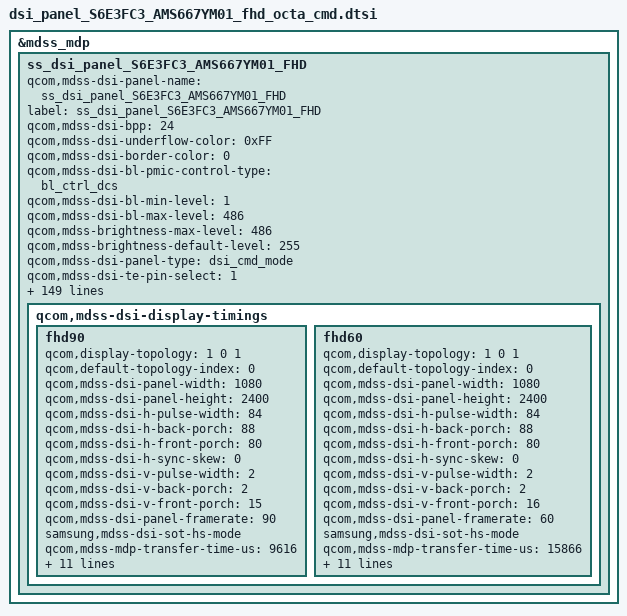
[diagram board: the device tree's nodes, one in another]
/* Copyright (c) 2020, Samsung Electronics Corporation. All rights reserved.
 *
 * This program is free software; you can redistribute it and/or modify
 * it under the terms of the GNU General Public License version 2 and
 * only version 2 as published by the Free Software Foundation.
 *
 * This program is distributed in the hope that it will be useful,
 * but WITHOUT ANY WARRANTY; without even the implied warranty of
 * MERCHANTABILITY or FITNESS FOR A PARTICULAR PURPOSE.  See the
 * GNU General Public License for more details.
 */

&mdss_mdp {
	ss_dsi_panel_S6E3FC3_AMS667YM01_FHD: ss_dsi_panel_S6E3FC3_AMS667YM01_FHD {
		qcom,mdss-dsi-panel-name = "ss_dsi_panel_S6E3FC3_AMS667YM01_FHD";
		label = "ss_dsi_panel_S6E3FC3_AMS667YM01_FHD";

		qcom,mdss-dsi-bpp = <24>;

		qcom,mdss-dsi-underflow-color = <0xFF>;
		qcom,mdss-dsi-border-color = <0>;

		qcom,mdss-dsi-bl-pmic-control-type = "bl_ctrl_dcs";

		qcom,mdss-dsi-bl-min-level = <1>;
		qcom,mdss-dsi-bl-max-level = <486>;
		qcom,mdss-brightness-max-level = <486>;
		qcom,mdss-brightness-default-level = <255>;

		qcom,mdss-dsi-panel-type = "dsi_cmd_mode";

		qcom,mdss-dsi-te-pin-select = <1>;

		qcom,mdss-dsi-te-dcs-command = <1>;
		qcom,mdss-dsi-wr-mem-start = <0x2C>;
		qcom,mdss-dsi-wr-mem-continue = <0x3C>;

		qcom,mdss-dsi-pixel-packing = "loose";

		qcom,mdss-dsi-virtual-channel-id = <0>;
		qcom,mdss-dsi-color-order = "rgb_swap_rgb";
		qcom,mdss-dsi-lane-0-state;
		qcom,mdss-dsi-lane-1-state;
		qcom,mdss-dsi-lane-2-state;
		qcom,mdss-dsi-lane-3-state;
		qcom,mdss-dsi-lane-map = "lane_map_0123";

		qcom,mdss-dsi-t-clk-pre = <0x3E>;
		qcom,mdss-dsi-t-clk-post = <0x10>;

		qcom,mdss-dsi-stream = <0>;
		qcom,mdss-dsi-mdp-trigger = "none";
		qcom,mdss-dsi-dma-trigger = "trigger_sw";

		qcom,mdss-pan-physical-width-dimension = <70>; /* 69.87 */
		qcom,mdss-pan-physical-height-dimension = <155>; /* 155.28 */

		qcom,mdss-dsi-reset-sequence = <0 10>, <1 10>;

		qcom,mdss-dsi-lp11-init;
		/*qcom,mdss-dsi-init-delay-us = <1000>;*/

		qcom,mdss-dsi-t-clk-pre-extend; /* Increment t_clk_pre counter by 2 byteclk */
		qcom,mdss-dsi-rx-eot-ignore;
		qcom,mdss-dsi-tx-eot-append;

		/* HDR Setting */
		/*qcom,mdss-dsi-panel-hdr-enabled;*/
		/*qcom,mdss-dsi-panel-hdr-color-primaries = <15635 16450 34000 16000 13250 34500 7500 3000>;*/
		/*qcom,mdss-dsi-panel-peak-brightness = <5400000>;*/
		/*qcom,mdss-dsi-panel-average-brightness = <2000000>;*/
		/*qcom,mdss-dsi-panel-blackness-level = <2000>;*/

		qcom,ulps-enabled;

		/* qcom,suspend-ulps-enabled; */
		//qcom,esd-check-enabled;
		//qcom,mdss-dsi-panel-status-check-mode ="irq_check";
		/*qcom,mdss-dsi-panel-status-read-length;*/
		/*qcom,mdss-dsi-panel-status-value;*/
		/*qcom,mdss-dsi-panel-status-irq-trigger1 = "rising";*/

		/* *************************************************************
		 * Below  parameters are samsung dependent thigs
		 * *************************************************************
		 */
		samsung,panel-vendor = "SDC";
		samsung,disp-model = "AMS667YM01";
		samsung,support_gamma_mode2;
		samsung,skip_read_on_pre;
		samsung,elvss_interpolation_temperature = <(-16)>;
		samsung,support_lpm;
		samsung,support_gpara;
		samsung,pointing_gpara;
		samsung,two_byte_gpara;
		samsung,rsc_4_frame_idle;
		samsung,support_factory_panel_swap;

		samsung,support-optical-fingerprint;

		samsung,support_vrr_based_bl; /* VRR Variable Refresh Rate */

		//samsung,esd-irq-trigger1 = "falling"; /* DISP_DET */
		//samsung,esd-irq-trigger2 = "falling"; /* FG_ERR */

		/* *************************************************************
		 *  SELF DISPLAY
		 * *************************************************************
		 */

		ss,self_display = <&self_display_FC3_dtsi>;

		/* *************************************************************
		 *  Tx
		 * *************************************************************
		 */

		samsung,level0_key_enable_tx_cmds_revA	= [29 01 00 00 00 00 03 9F A5 A5]; /* PASSWD0 */
		samsung,level0_key_disable_tx_cmds_revA	= [29 01 00 00 00 00 03 9F 5A 5A]; /* PASSWD0 */
		samsung,level1_key_enable_tx_cmds_revA	= [29 01 00 00 00 00 03 F0 5A 5A]; /* PASSWD1 */
		samsung,level1_key_disable_tx_cmds_revA	= [29 01 00 00 00 00 03 F0 A5 A5]; /* PASSWD1 */
		samsung,level2_key_enable_tx_cmds_revA	= [29 01 00 00 00 00 03 FC 5A 5A];
		samsung,level2_key_disable_tx_cmds_revA	= [29 01 00 00 00 00 03 FC A5 A5];

		/* BRIGHTNESS_MAX_PACKET = 50 */
		samsung,brightness_tx_cmds_revA = [
			39 01 00 00 00 00 01 00
			39 01 00 00 00 00 01 00
			39 01 00 00 00 00 01 00
			39 01 00 00 00 00 01 00
			39 01 00 00 00 00 01 00
			39 01 00 00 00 00 01 00
			39 01 00 00 00 00 01 00
			39 01 00 00 00 00 01 00
			39 01 00 00 00 00 01 00
			39 01 00 00 00 00 01 00
			39 01 00 00 00 00 01 00
			39 01 00 00 00 00 01 00
			39 01 00 00 00 00 01 00
			39 01 00 00 00 00 01 00
			39 01 00 00 00 00 01 00
			39 01 00 00 00 00 01 00
			39 01 00 00 00 00 01 00
			39 01 00 00 00 00 01 00
			39 01 00 00 00 00 01 00
			39 01 00 00 00 00 01 00
			39 01 00 00 00 00 01 00
			39 01 00 00 00 00 01 00
			39 01 00 00 00 00 01 00
			39 01 00 00 00 00 01 00
			39 01 00 00 00 00 01 00
			39 01 00 00 00 00 01 00
			39 01 00 00 00 00 01 00
			39 01 00 00 00 00 01 00
			39 01 00 00 00 00 01 00
			39 01 00 00 00 00 01 00
			39 01 00 00 00 00 01 00
			39 01 00 00 00 00 01 00
			39 01 00 00 00 00 01 00
			39 01 00 00 00 00 01 00
			39 01 00 00 00 00 01 00
			39 01 00 00 00 00 01 00
			39 01 00 00 00 00 01 00
			39 01 00 00 00 00 01 00
			39 01 00 00 00 00 01 00
			39 01 00 00 00 00 01 00
			39 01 00 00 00 00 01 00
			39 01 00 00 00 00 01 00
			39 01 00 00 00 00 01 00
			39 01 00 00 00 00 01 00
			39 01 00 00 00 00 01 00
			39 01 00 00 00 00 01 00
			39 01 00 00 00 00 01 00
			39 01 00 00 00 00 01 00
			39 01 00 00 00 00 01 00
			39 01 00 00 00 00 01 00
		];

		samsung,display_on_tx_cmds_revA = [
			/* DSC PPS cmd unlock & lock LEVEL0 KEY */
			29 00 00 00 00 00 03 9F A5 A5
			05 00 00 00 00 00 02 29 00
			29 01 00 00 00 00 03 9F 5A 5A
		];

		samsung,display_off_tx_cmds_revA = [05 01 00 00 00 00 02 28 00];

		samsung,reg_read_pos_tx_cmds_revA = [29 00 00 00 00 00 04 B0 00 00 00];

		samsung,mtp_write_sysfs_tx_cmds_revA = [
			29 00 00 00 00 00 3D 00
			00 00 00 00 00 00 00 00 00 00
			00 00 00 00 00 00 00 00 00 00
			00 00 00 00 00 00 00 00 00 00
			00 00 00 00 00 00 00 00 00 00
			00 00 00 00 00 00 00 00 00 00
			00 00 00 00 00 00 00 00 00 00
		];

		samsung,panel_ltps_tx_cmds_revA = [
			29 00 00 00 00 00 03 F0 5A 5A
			29 00 00 00 00 00 03 9F A5 A5

			/* Global Para Setting */
			29 00 00 00 00 00 2A F2
				00 05 0E 58 50 01 0C 00
				04 26 E4 2F B0 0C 09 74
				26 E4 0C 00 04 10 00 10
				26 A8 10 00 10 10 3C 10
				00 40 30 C8 00 C8 00 00
				CE

			/* Freq setting */
			29 00 00 00 00 00 04 B0 00 27 F2
			29 00 00 00 00 00 02 F2 00

			/* Panel Update */
			29 00 00 00 00 00 02 F7 0F

			29 00 00 00 00 00 03 9F 5A 5A
			29 01 00 00 00 00 03 F0 A5 A5
		];

		samsung,panel_ltps_tx_cmds_revC = [
			29 00 00 00 00 00 03 F0 5A 5A
			29 00 00 00 00 00 03 9F A5 A5

			/* Global Para Setting */
			29 00 00 00 00 00 2A F2
				00 05 0E 58 50 00 0C 00
				04 31 48 31 48 0C 04 BC
				26 E8 0C 00 04 10 00 10
				26 A8 10 00 10 10 3C 10
				00 40 30 C8 00 C8 00 00
				CE
			/* Freq setting */
			29 00 00 00 00 00 04 B0 00 27 F2
			29 00 00 00 00 00 02 F2 00

			/* Panel Update */
			29 00 00 00 00 00 02 F7 0F

			29 00 00 00 00 00 03 9F 5A 5A
			29 01 00 00 00 00 03 F0 A5 A5
		];

		samsung,smooth_dimming_off_tx_cmds_revA = [
			29 00 00 00 00 00 03 F0 5A 5A
			29 00 00 00 00 00 04 B0 00 91 63
			29 00 00 00 00 00 02 63 20
			29 01 00 00 11 00 02 53 20
			29 00 00 00 00 00 02 F7 0F
			29 01 00 00 00 00 03 F0 A5 A5
		];

		samsung,gamma_mode2_normal_tx_cmds_revG=[
			29 00 00 00 00 00 04 B0 00 91 63
			29 00 00 00 00 00 02 63 60	/* Dimming Speed Sync Control */
			29 00 00 00 00 00 04 B0 02 03 63
			29 00 00 00 00 00 03 63 f1 07	/* For Finger Print */
			29 00 00 00 00 00 02 53 20	/* Dimming Speed setting */
			29 00 00 00 00 00 03 51 03 FF	/* WRDISBV */
			29 00 00 00 00 00 02 B5 14	/* temperature */
			29 00 00 00 00 00 04 B0 02 03 63
			29 00 00 00 00 00 03 63 f0 00	/* For Finger Print */
			29 00 00 00 00 00 04 B0 00 76 63
			29 00 00 00 00 00 04 63 00 00 00 /* AOR */
		];

		samsung,gamma_mode2_normal_tx_cmds_revF=[
			29 00 00 00 00 00 03 91 02 01	 /* normal brightness */
			29 00 00 00 00 00 02 53 20	/* dimming speed setting */
			29 00 00 00 00 00 03 51 03 FF	/* WRDISBV */
			29 00 00 00 00 00 02 B5 14	/* temperature */
			29 00 00 00 00 00 04 B0 00 76 63
			29 00 00 00 00 00 04 63 00 00 00 /* AOR */
		];

		samsung,gamma_mode2_normal_tx_cmds_revA=[
			29 00 00 00 00 00 04 B0 00 02 90
			29 00 00 00 00 00 02 90 1C	 /* normal brightness */
			29 00 00 00 00 00 02 53 20	/* dimming speed setting */
			29 00 00 00 00 00 03 51 03 FF	/* WRDISBV */
			29 00 00 00 00 00 02 B5 14	/* temperature */
			29 00 00 00 00 00 04 B0 00 76 63
			29 00 00 00 00 00 04 63 00 00 00 /* AOR */
		];

		samsung,gamma_mode2_hbm_tx_cmds_revG=[
			29 00 00 00 00 00 04 B0 00 91 63
			29 00 00 00 00 00 02 63 20	/* Dimming Speed Sync Control */
			29 00 00 00 00 00 04 B0 02 03 63
			29 00 00 00 00 00 03 63 f1 00	/* For Finger Print */
			29 00 00 00 00 00 02 53 E0	/* Dimming Speed setting */
			29 00 00 00 00 00 03 51 03 FF	/* WRDISBV */
			29 00 00 00 00 00 02 B5 14	/* temperature */
			29 00 00 00 00 00 04 B0 02 03 63
			29 00 00 00 00 00 03 63 f0 07	/* For Finger Print */
			29 00 00 00 00 00 04 B0 00 76 63
			29 00 00 00 00 00 04 63 00 00 00 /* AOR */
		];

		samsung,gamma_mode2_hbm_tx_cmds_revF=[
			29 00 00 00 00 00 03 91 02 00	 /* hbm brightness */
			29 00 00 00 00 00 02 53 E0	/* dimming speed setting */
			29 00 00 00 00 00 03 51 03 FF	/* WRDISBV */
			29 00 00 00 00 00 02 B5 14	/* temperature */
			29 00 00 00 00 00 04 B0 00 76 63
			29 00 00 00 00 00 04 63 00 00 00 /* AOR */
		];

		samsung,gamma_mode2_hbm_tx_cmds_revA=[
			29 00 00 00 00 00 04 B0 00 02 90
			29 00 00 00 00 00 02 90 14	 /* hbm brightness */
			29 00 00 00 00 00 02 53 E0	/* dimming speed setting */
			29 00 00 00 00 00 03 51 03 FF	/* WRDISBV */
			29 00 00 00 00 00 02 B5 14	/* temperature */
			29 00 00 00 00 00 04 B0 00 76 63
			29 00 00 00 00 00 04 63 00 00 00 /* AOR */
		];

		samsung,vrr_tx_cmds_revA = [
			29 00 00 00 00 00 03 60 00 00
			29 00 00 00 00 00 02 F7 0F
		];

		samsung,acl_on_tx_cmds_revA = [
			29 00 00 00 00 00 04 B0 03 B3 65
			29 00 00 00 00 00 14 65
				55 00 B0 51 66 98 15 55 55 55	/* 32 Frame Avg & ACL start step 50% */
				08 F1 C6 48 40 00 20 10 09	/* ACL Dimming : 32 frame */
			29 00 00 00 00 00 02 55 03		/* normal ACL 15% & HBM ACL 8% */
		];

		samsung,acl_off_tx_cmds_revA = [
			29 01 00 00 00 00 02 55 00	/* ACL OFF */
		];

		/* *************************************************************
		 *  Rx (Module Information READ)
		 * *************************************************************
		 */
		samsung,manufacture_id0_rx_cmds_revA	= [06 01 00 00 00 00 01 da 01 00 00];
		samsung,manufacture_id1_rx_cmds_revA	= [06 01 00 00 00 00 01 db 01 00 00];
		samsung,manufacture_id2_rx_cmds_revA	= [06 01 00 00 00 00 01 dc 01 00 00];

		samsung,module_info_rx_cmds_revA = [06 01 00 00 00 00 01 A1 0B 00 00];
		samsung,octa_id_rx_cmds_revA	= [06 01 00 00 00 00 01 A1 04 00 0B]; /* OCTA ID : read A1 12th ~ 15th + Cell ID */
		samsung,cell_id_rx_cmds_revA	= [06 01 00 00 00 00 01 A1 10 00 0F]; /* CELL ID : read A1 16th ~ 31th bytes*/
		samsung,cell_id_rx_cmds_revG	= [06 01 00 00 00 00 01 92 10 00 02]; /* CELL ID : read 92 3rd ~ 18th bytes*/
		samsung,ddi_id_rx_cmds_revA		= [06 01 00 00 00 00 01 D6 05 00 00];

		samsung,mtp_read_sysfs_rx_cmds_revA = [06 01 00 00 00 00 01 00 00 00 00];


		/* *************************************************************
		 * candela to index mappings
		 * **************************************************************
		 */
		samsung,candela_map_table_revA = < /* THIS TABLE USED FOR DIMMING */
		/* <idx> <from> <till> <gm2_wrdisbv> <cd> */
			0	0	0	2	2
			1	1	1	3	2
			2	2	2	4	3
			3	3	3	5	3
			4	4	4	7	4
			5	5	5	8	5
			6	6	6	10	5
			7	7	7	12	6
			8	8	8	13	7
			9	9	9	15	7
			10	10	10	17	8
			11	11	11	19	9
			12	12	12	21	10
			13	13	13	24	11
			14	14	14	26	12
			15	15	15	28	13
			16	16	16	30	13
			17	17	17	32	14
			18	18	18	35	15
			19	19	19	37	16
			20	20	20	40	17
			21	21	21	42	18
			22	22	22	45	19
			23	23	23	47	20
			24	24	24	50	21
			25	25	25	52	22
			26	26	26	55	23
			27	27	27	58	25
			28	28	28	60	26
			29	29	29	63	27
			30	30	30	66	28
			31	31	31	69	29
			32	32	32	71	30
			33	33	33	74	31
			34	34	34	77	32
			35	35	35	80	34
			36	36	36	83	35
			37	37	37	86	36
			38	38	38	89	37
			39	39	39	92	38
			40	40	40	95	40
			41	41	41	98	41
			42	42	42	101	42
			43	43	43	104	43
			44	44	44	107	45
			45	45	45	110	46
			46	46	46	113	47
			47	47	47	116	48
			48	48	48	119	50
			49	49	49	123	51
			50	50	50	126	52
			51	51	51	129	54
			52	52	52	132	55
			53	53	53	136	56
			54	54	54	139	58
			55	55	55	142	59
			56	56	56	146	60
			57	57	57	149	62
			58	58	58	152	63
			59	59	59	156	64
			60	60	60	159	66
			61	61	61	162	67
			62	62	62	166	68
			63	63	63	169	70
			64	64	64	173	71
			65	65	65	176	73
			66	66	66	180	74
			67	67	67	183	76
			68	68	68	187	77
			69	69	69	190	78
			70	70	70	194	80
			71	71	71	197	81
			72	72	72	201	83
			73	73	73	205	84
			74	74	74	208	86
			75	75	75	212	87
			76	76	76	215	89
			77	77	77	219	90
			78	78	78	223	92
			79	79	79	227	93
			80	80	80	230	95
			81	81	81	234	96
			82	82	82	238	98
			83	83	83	241	99
			84	84	84	245	101
			85	85	85	249	102
			86	86	86	253	104
			87	87	87	257	105
			88	88	88	260	107
			89	89	89	264	108
			90	90	90	268	110
			91	91	91	272	112
			92	92	92	276	113
			93	93	93	280	115
			94	94	94	283	116
			95	95	95	287	118
			96	96	96	291	119
			97	97	97	295	121
			98	98	98	299	123
			99	99	99	303	124
			100	100	100	307	126
			101	101	101	311	127
			102	102	102	315	129
			103	103	103	319	131
			104	104	104	323	132
			105	105	105	327	134
			106	106	106	331	136
			107	107	107	335	137
			108	108	108	339	139
			109	109	109	343	140
			110	110	110	347	142
			111	111	111	351	144
			112	112	112	355	145
			113	113	113	360	147
			114	114	114	364	149
			115	115	115	368	150
			116	116	116	372	152
			117	117	117	376	154
			118	118	118	380	156
			119	119	119	384	157
			120	120	120	389	159
			121	121	121	393	161
			122	122	122	397	162
			123	123	123	401	164
			124	124	124	405	166
			125	125	125	410	167
			126	126	126	414	169
			127	127	127	418	171
			128	128	128	422	173
			129	129	129	427	174
			130	130	130	431	176
			131	131	131	435	178
			132	132	132	440	180
			133	133	133	444	181
			134	134	134	448	183
			135	135	135	453	185
			136	136	136	457	187
			137	137	137	461	188
			138	138	138	465	190
			139	139	139	470	192
			140	140	140	474	194
			141	141	141	478	195
			142	142	142	483	197
			143	143	143	487	199
			144	144	144	491	201
			145	145	145	496	203
			146	146	146	500	204
			147	147	147	504	206
			148	148	148	509	208
			149	149	149	513	210
			150	150	150	518	212
			151	151	151	522	214
			152	152	152	526	215
			153	153	153	531	217
			154	154	154	535	219
			155	155	155	540	221
			156	156	156	544	223
			157	157	157	549	225
			158	158	158	553	226
			159	159	159	558	228
			160	160	160	562	230
			161	161	161	567	232
			162	162	162	571	234
			163	163	163	576	236
			164	164	164	580	237
			165	165	165	585	239
			166	166	166	589	241
			167	167	167	594	243
			168	168	168	598	245
			169	169	169	603	247
			170	170	170	608	249
			171	171	171	612	251
			172	172	172	617	253
			173	173	173	621	254
			174	174	174	626	256
			175	175	175	631	258
			176	176	176	635	260
			177	177	177	640	262
			178	178	178	644	264
			179	179	179	649	266
			180	180	180	654	268
			181	181	181	658	270
			182	182	182	663	272
			183	183	183	668	274
			184	184	184	672	275
			185	185	185	677	277
			186	186	186	682	279
			187	187	187	686	281
			188	188	188	691	283
			189	189	189	696	285
			190	190	190	701	287
			191	191	191	705	289
			192	192	192	710	291
			193	193	193	715	293
			194	194	194	720	295
			195	195	195	724	297
			196	196	196	729	299
			197	197	197	734	301
			198	198	198	739	303
			199	199	199	744	305
			200	200	200	748	307
			201	201	201	753	309
			202	202	202	758	311
			203	203	203	763	313
			204	204	204	768	315
			205	205	205	772	317
			206	206	206	777	319
			207	207	207	782	321
			208	208	208	787	323
			209	209	209	792	325
			210	210	210	797	327
			211	211	211	802	329
			212	212	212	807	331
			213	213	213	811	333
			214	214	214	816	335
			215	215	215	821	337
			216	216	216	826	339
			217	217	217	831	341
			218	218	218	836	343
			219	219	219	841	345
			220	220	220	846	347
			221	221	221	851	349
			222	222	222	856	351
			223	223	223	861	353
			224	224	224	866	355
			225	225	225	871	357
			226	226	226	876	359
			227	227	227	881	361
			228	228	228	886	363
			229	229	229	891	365
			230	230	230	896	368
			231	231	231	901	370
			232	232	232	906	372
			233	233	233	911	374
			234	234	234	916	376
			235	235	235	921	378
			236	236	236	926	380
			237	237	237	931	382
			238	238	238	936	384
			239	239	239	941	386
			240	240	240	946	388
			241	241	241	951	390
			242	242	242	956	393
			243	243	243	961	395
			244	244	244	967	397
			245	245	245	972	399
			246	246	246	977	401
			247	247	247	982	403
			248	248	248	987	405
			249	249	249	992	407
			250	250	250	997	409
			251	251	251	1002	411
			252	252	252	1008	414
			253	253	253	1013	416
			254	254	254	1018	418
			255	255	255	1023	420
		>;

		samsung,hbm_candela_map_table_revG = <
		/* <idx> <from> <till> <gm2_wrdisbv> <cd>*/
			0	256	256	0	425
			1	257	257	2	426
			2	258	258	4	428
			3	259	259	6	430
			4	260	260	8	432
			5	261	261	10	433
			6	262	262	12	435
			7	263	263	14	436
			8	264	264	16	438
			9	265	265	18	440
			10	266	266	20	441
			11	267	267	22	443
			12	268	268	24	444
			13	269	269	26	446
			14	270	270	28	448
			15	271	271	30	450
			16	272	272	32	451
			17	273	273	34	453
			18	274	274	36	454
			19	275	275	37	456
			20	276	276	38	458
			21	277	277	39	459
			22	278	278	40	461
			23	279	279	41	462
			24	280	280	42	464
			25	281	281	43	466
			26	282	282	44	468
			27	283	283	45	469
			28	284	284	46	471
			29	285	285	47	472
			30	286	286	48	474
			31	287	287	49	476
			32	288	288	50	477
			33	289	289	51	479
			34	290	290	52	480
			35	291	291	53	482
			36	292	292	54	484
			37	293	293	55	485
			38	294	294	56	487
			39	295	295	57	488
			40	296	296	58	490
			41	297	297	59	492
			42	298	298	60	494
			43	299	299	61	495
			44	300	300	62	497
			45	301	301	63	498
			46	302	302	64	500
			47	303	303	65	502
			48	304	304	66	503
			49	305	305	67	505
			50	306	306	68	506
			51	307	307	69	508
			52	308	308	70	510
			53	309	309	71	512
			54	310	310	72	513
			55	311	311	73	515
			56	312	312	74	516
			57	313	313	75	518
			58	314	314	76	520
			59	315	315	77	521
			60	316	316	78	523
			61	317	317	79	524
			62	318	318	80	526
			63	319	319	81	528
			64	320	320	82	529
			65	321	321	83	531
			66	322	322	84	533
			67	323	323	85	534
			68	324	324	86	536
			69	325	325	87	538
			70	326	326	88	539
			71	327	327	89	541
			72	328	328	90	542
			73	329	329	91	544
			74	330	330	92	546
			75	331	331	93	547
			76	332	332	95	549
			77	333	333	97	550
			78	334	334	99	552
			79	335	335	101	554
			80	336	336	103	555
			81	337	337	105	557
			82	338	338	107	559
			83	339	339	109	560
			84	340	340	111	562
			85	341	341	113	564
			86	342	342	115	565
			87	343	343	117	567
			88	344	344	119	568
			89	345	345	121	570
			90	346	346	123	572
			91	347	347	125	573
			92	348	348	127	575
			93	349	349	129	577
			94	350	350	131	578
			95	351	351	133	580
			96	352	352	135	582
			97	353	353	137	583
			98	354	354	139	585
			99	355	355	141	586
			100	356	356	143	588
			101	357	357	145	590
			102	358	358	147	591
			103	359	359	149	593
			104	360	360	151	595
			105	361	361	154	596
			106	362	362	157	598
			107	363	363	160	599
			108	364	364	163	601
			109	365	365	166	603
			110	366	366	168	604
			111	367	367	171	606
			112	368	368	174	608
			113	369	369	177	609
			114	370	370	180	611
			115	371	371	183	612
			116	372	372	186	614
			117	373	373	189	616
			118	374	374	192	617
			119	375	375	195	619
			120	376	376	198	621
			121	377	377	201	622
			122	378	378	204	624
			123	379	379	207	626
			124	380	380	210	627
			125	381	381	213	629
			126	382	382	216	630
			127	383	383	219	632
			128	384	384	222	634
			129	385	385	225	635
			130	386	386	228	637
			131	387	387	231	639
			132	388	388	234	640
			133	389	389	237	642
			134	390	390	240	643
			135	391	391	243	645
			136	392	392	246	647
			137	393	393	249	648
			138	394	394	252	650
			139	395	395	255	652
			140	396	396	258	653
			141	397	397	261	655
			142	398	398	264	657
			143	399	399	267	658
			144	400	400	270	660
			145	401	401	273	661
			146	402	402	276	663
			147	403	403	279	665
			148	404	404	282	666
			149	405	405	285	668
			150	406	406	288	670
			151	407	407	291	671
			152	408	408	294	673
			153	409	409	297	675
			154	410	410	300	676
			155	411	411	303	678
			156	412	412	306	679
			157	413	413	309	681
			158	414	414	312	683
			159	415	415	315	684
			160	416	416	318	686
			161	417	417	321	687
			162	418	418	324	689
			163	419	419	327	691
			164	420	420	330	692
			165	421	421	333	694
			166	422	422	336	696
			167	423	423	339	697
			168	424	424	342	699
			169	425	425	345	701
			170	426	426	348	702
			171	427	427	351	704
			172	428	428	354	705
			173	429	429	357	707
			174	430	430	360	709
			175	431	431	363	710
			176	432	432	366	712
			177	433	433	369	713
			178	434	434	372	715
			179	435	435	375	717
			180	436	436	378	719
			181	437	437	381	720
			182	438	438	384	722
			183	439	439	387	723
			184	440	440	390	725
			185	441	441	393	727
			186	442	442	396	728
			187	443	443	399	730
			188	444	444	402	731
			189	445	445	405	733
			190	446	446	408	735
			191	447	447	411	737
			192	448	448	414	738
			193	449	449	417	740
			194	450	450	420	741
			195	451	451	423	743
			196	452	452	426	745
			197	453	453	429	746
			198	454	454	432	748
			199	455	455	435	749
			200	456	456	438	751
			201	457	457	441	753
			202	458	458	444	754
			203	459	459	447	756
			204	460	460	450	757
			205	461	461	453	759
			206	462	462	456	761
			207	463	463	459	763
			208	464	464	462	764
			209	465	465	465	766
			210	466	466	468	767
			211	467	467	471	769
			212	468	468	474	771
			213	469	469	477	772
			214	470	470	480	774
			215	471	471	483	775
			216	472	472	486	777
			217	473	473	489	779
			218	474	474	492	781
			219	475	475	495	782
			220	476	476	498	784
			221	477	477	501	785
			222	478	478	504	787
			223	479	479	507	789
			224	480	480	510	790
			225	481	481	513	792
			226	482	482	516	793
			227	483	483	519	795
			228	484	484	522	797
			229	485	485	525	799
			230	486	486	528	800
		>;

		samsung,hbm_candela_map_table_revA = <
		/* <idx> <from> <till> <gm2_wrdisbv> <cd>*/
			0	256	256	0	425
			1	257	257	3	426
			2	258	258	6	428
			3	259	259	9	430
			4	260	260	12	432
			5	261	261	15	433
			6	262	262	18	435
			7	263	263	21	436
			8	264	264	24	438
			9	265	265	27	440
			10	266	266	30	441
			11	267	267	33	443
			12	268	268	36	444
			13	269	269	39	446
			14	270	270	42	448
			15	271	271	45	450
			16	272	272	48	451
			17	273	273	51	453
			18	274	274	54	454
			19	275	275	57	456
			20	276	276	60	458
			21	277	277	63	459
			22	278	278	66	461
			23	279	279	69	462
			24	280	280	72	464
			25	281	281	75	466
			26	282	282	78	468
			27	283	283	81	469
			28	284	284	84	471
			29	285	285	86	472
			30	286	286	88	474
			31	287	287	90	476
			32	288	288	92	477
			33	289	289	94	479
			34	290	290	96	480
			35	291	291	98	482
			36	292	292	100	484
			37	293	293	102	485
			38	294	294	104	487
			39	295	295	106	488
			40	296	296	108	490
			41	297	297	110	492
			42	298	298	112	494
			43	299	299	114	495
			44	300	300	116	497
			45	301	301	118	498
			46	302	302	120	500
			47	303	303	122	502
			48	304	304	124	503
			49	305	305	126	505
			50	306	306	128	506
			51	307	307	130	508
			52	308	308	132	510
			53	309	309	134	512
			54	310	310	136	513
			55	311	311	138	515
			56	312	312	140	516
			57	313	313	142	518
			58	314	314	144	520
			59	315	315	146	521
			60	316	316	148	523
			61	317	317	150	524
			62	318	318	152	526
			63	319	319	154	528
			64	320	320	156	529
			65	321	321	158	531
			66	322	322	160	533
			67	323	323	162	534
			68	324	324	164	536
			69	325	325	166	538
			70	326	326	168	539
			71	327	327	170	541
			72	328	328	172	542
			73	329	329	174	544
			74	330	330	176	546
			75	331	331	178	547
			76	332	332	182	549
			77	333	333	186	550
			78	334	334	190	552
			79	335	335	194	554
			80	336	336	198	555
			81	337	337	203	557
			82	338	338	208	559
			83	339	339	213	560
			84	340	340	218	562
			85	341	341	223	564
			86	342	342	228	565
			87	343	343	233	567
			88	344	344	238	568
			89	345	345	243	570
			90	346	346	248	572
			91	347	347	253	573
			92	348	348	258	575
			93	349	349	263	577
			94	350	350	268	578
			95	351	351	273	580
			96	352	352	278	582
			97	353	353	283	583
			98	354	354	288	585
			99	355	355	293	586
			100	356	356	298	588
			101	357	357	303	590
			102	358	358	308	591
			103	359	359	313	593
			104	360	360	318	595
			105	361	361	323	596
			106	362	362	328	598
			107	363	363	333	599
			108	364	364	338	601
			109	365	365	343	603
			110	366	366	348	604
			111	367	367	353	606
			112	368	368	358	608
			113	369	369	363	609
			114	370	370	368	611
			115	371	371	373	612
			116	372	372	378	614
			117	373	373	383	616
			118	374	374	388	617
			119	375	375	393	619
			120	376	376	398	621
			121	377	377	403	622
			122	378	378	408	624
			123	379	379	413	626
			124	380	380	418	627
			125	381	381	423	629
			126	382	382	428	630
			127	383	383	433	632
			128	384	384	438	634
			129	385	385	443	635
			130	386	386	448	637
			131	387	387	453	639
			132	388	388	458	640
			133	389	389	463	642
			134	390	390	468	643
			135	391	391	473	645
			136	392	392	478	647
			137	393	393	483	648
			138	394	394	488	650
			139	395	395	493	652
			140	396	396	498	653
			141	397	397	503	655
			142	398	398	508	657
			143	399	399	513	658
			144	400	400	518	660
			145	401	401	523	661
			146	402	402	528	663
			147	403	403	533	665
			148	404	404	538	666
			149	405	405	543	668
			150	406	406	548	670
			151	407	407	553	671
			152	408	408	558	673
			153	409	409	563	675
			154	410	410	568	676
			155	411	411	573	678
			156	412	412	578	679
			157	413	413	583	681
			158	414	414	589	683
			159	415	415	595	684
			160	416	416	601	686
			161	417	417	607	687
			162	418	418	613	689
			163	419	419	619	691
			164	420	420	625	692
			165	421	421	631	694
			166	422	422	637	696
			167	423	423	643	697
			168	424	424	649	699
			169	425	425	655	701
			170	426	426	661	702
			171	427	427	667	704
			172	428	428	673	705
			173	429	429	679	707
			174	430	430	685	709
			175	431	431	691	710
			176	432	432	697	712
			177	433	433	703	713
			178	434	434	709	715
			179	435	435	715	717
			180	436	436	721	719
			181	437	437	727	720
			182	438	438	733	722
			183	439	439	739	723
			184	440	440	745	725
			185	441	441	751	727
			186	442	442	757	728
			187	443	443	763	730
			188	444	444	769	731
			189	445	445	775	733
			190	446	446	781	735
			191	447	447	787	737
			192	448	448	793	738
			193	449	449	799	740
			194	450	450	805	741
			195	451	451	811	743
			196	452	452	817	745
			197	453	453	823	746
			198	454	454	829	748
			199	455	455	835	749
			200	456	456	841	751
			201	457	457	847	753
			202	458	458	853	754
			203	459	459	859	756
			204	460	460	865	757
			205	461	461	871	759
			206	462	462	877	761
			207	463	463	883	763
			208	464	464	889	764
			209	465	465	895	766
			210	466	466	901	767
			211	467	467	907	769
			212	468	468	913	771
			213	469	469	919	772
			214	470	470	925	774
			215	471	471	931	775
			216	472	472	937	777
			217	473	473	943	779
			218	474	474	949	781
			219	475	475	955	782
			220	476	476	961	784
			221	477	477	967	785
			222	478	478	973	787
			223	479	479	979	789
			224	480	480	985	790
			225	481	481	991	792
			226	482	482	997	793
			227	483	483	1003	795
			228	484	484	1009	797
			229	485	485	1015	799
			230	486	486	1023	800
		>;

		samsung,aod_candela_map_table_revA = <
		/*   <idx>   <from>  <till>  <gm2_wrdisbv> <cd> */
			0	0	11	27	2
			1	12	31	26	10
			2	32	54	25	30
			3	55	255	24	60
		>;

		/* *************************************************************
		 * Dynamic MIPI Clock
		 * **************************************************************
		 */
		samsung,support_dynamic_mipi_clk;

		samsung,ffc_tx_cmds_revA = [
			29 00 00 00 00 00 03 F0 5A 5A
			29 00 00 00 00 00 03 FC 5A 5A

			/* 0. Default 1711 Mbps */
			29 00 00 00 00 00 04 B0 00 2A C5
			29 00 00 00 00 00 05 C5 0D 10 80 45
			29 00 00 00 00 00 04 B0 00 2E C5
			29 00 00 00 00 00 03 C5 36 41

			29 00 00 00 00 00 02 F7 0F
			29 00 00 00 00 00 03 FC A5 A5
			29 00 00 00 00 00 03 F0 A5 A5
		];

		samsung,ffc_tx_cmds_revC = [
			29 00 00 00 00 00 03 F0 5A 5A
			29 00 00 00 00 00 03 FC 5A 5A

			/* 0. Default 1711 Mbps */
			29 00 00 00 00 00 04 B0 00 2A C5
			29 00 00 00 00 00 05 C5 0D 10 80 45
			29 00 00 00 00 00 04 B0 00 3E C5
			29 00 00 00 00 00 03 C5 33 43

			29 00 00 00 00 00 02 F7 0F
			29 00 00 00 00 00 03 FC A5 A5
			29 00 00 00 00 00 03 F0 A5 A5
		];

		samsung,ffc_tx_cmds_revD = [
			29 00 00 00 00 00 03 F0 5A 5A
			29 00 00 00 00 00 03 FC 5A 5A

			/* 0. Default 1711 Mbps */
			29 00 00 00 00 00 04 B0 00 2A C5
			29 00 00 00 00 00 05 C5 0D 10 80 45
			29 00 00 00 00 00 04 B0 00 3E C5
			29 00 00 00 00 00 03 C5 32 B1

			29 00 00 00 00 00 02 F7 0F
			29 00 00 00 00 00 03 FC A5 A5
			29 00 00 00 00 00 03 F0 A5 A5
		];

		samsung,dyn_mipi_clk_ffc_cmds_revA = [
			/* 0. Default 1711 Mbps */
			29 00 00 00 00 00 04 B0 00 2A C5
			29 00 00 00 00 00 05 C5 0D 10 80 45
			29 00 00 00 00 00 04 B0 00 2E C5
			29 00 00 00 00 00 03 C5 36 41

			/* 1. Default 1730 Mbps */
			29 00 00 00 00 00 04 B0 00 2A C5
			29 00 00 00 00 00 05 C5 0D 10 80 45
			29 00 00 00 00 00 04 B0 00 2E C5
			29 00 00 00 00 00 03 C5 35 A8

			/* 2. Default 1680 Mbps */
			29 00 00 00 00 00 04 B0 00 2A C5
			29 00 00 00 00 00 05 C5 0D 10 80 45
			29 00 00 00 00 00 04 B0 00 2E C5
			29 00 00 00 00 00 03 C5 37 41
		];

		samsung,dyn_mipi_clk_ffc_cmds_revC = [
			/* 0. Default 1711 Mbps */
			29 00 00 00 00 00 04 B0 00 2A C5
			29 00 00 00 00 00 05 C5 0D 10 80 45
			29 00 00 00 00 00 04 B0 00 3E C5
			29 00 00 00 00 00 03 C5 33 43

			/* 1. Default 1730 Mbps */
			29 00 00 00 00 00 04 B0 00 2A C5
			29 00 00 00 00 00 05 C5 0D 10 80 45
			29 00 00 00 00 00 04 B0 00 3E C5
			29 00 00 00 00 00 03 C5 32 B2

			/* 2. Default 1680 Mbps */
			29 00 00 00 00 00 04 B0 00 2A C5
			29 00 00 00 00 00 05 C5 0D 10 80 45
			29 00 00 00 00 00 04 B0 00 3E C5
			29 00 00 00 00 00 03 C5 34 35
		];

		samsung,dyn_mipi_clk_ffc_cmds_revD = [
			/* 0. Default 1711 Mbps */
			29 00 00 00 00 00 04 B0 00 2A C5
			29 00 00 00 00 00 05 C5 0D 10 80 45
			29 00 00 00 00 00 04 B0 00 3E C5
			29 00 00 00 00 00 03 C5 32 B1

			/* 1. Default 1730 Mbps */
			29 00 00 00 00 00 04 B0 00 2A C5
			29 00 00 00 00 00 05 C5 0D 10 80 45
			29 00 00 00 00 00 04 B0 00 3E C5
			29 00 00 00 00 00 03 C5 32 22

			/* 2. Default 1680 Mbps */
			29 00 00 00 00 00 04 B0 00 2A C5
			29 00 00 00 00 00 05 C5 0D 10 80 45
			29 00 00 00 00 00 04 B0 00 3E C5
			29 00 00 00 00 00 03 C5 33 A0
		];

		samsung,dynamic_mipi_clk_timing_table = <
			/*<bitclk><>*/
			1711000000 /* clk id 0 default */
			1730000000 /* clk id 1 */
			1680000000 /* clk id 2 */
		>;

		samsung,dynamic_mipi_clk_sel_table = <
			/*<RAT><BAND><from><end><clk index>*/
			1	1	0	0	0
			1	2	0	0	2
			1	3	0	0	2
			1	4	0	0	1
			2	11	10562	10658	0
			2	11	10659	10728	1
			2	11	10729	10838	0
			2	12	9662	9938	0
			2	13	1162	1357	0
			2	13	1358	1427	1
			2	13	1428	1513	0
			2	14	1537	1633	0
			2	14	1634	1703	1
			2	14	1704	1738	0
			2	15	4357	4458	0
			2	17	2237	2278	0
			2	17	2279	2348	1
			2	17	2349	2563	0
			2	18	2937	2950	1
			2	18	2951	2968	2
			2	18	2969	3088	0
			3	91	0	217	0
			3	91	218	357	1
			3	91	358	599	0
			3	92	600	618	1
			3	92	619	1191	0
			3	92	1192	1199	1
			3	93	1200	1615	0
			3	93	1616	1755	1
			3	93	1756	1949	0
			3	94	1950	2167	0
			3	94	2168	2307	1
			3	94	2308	2399	0
			3	95	2400	2649	0
			3	97	2750	2857	0
			3	97	2858	2997	1
			3	97	2998	3449	0
			3	98	3450	3500	1
			3	98	3501	3537	2
			3	98	3538	3799	0
			3	102	5010	5179	0
			3	103	5180	5279	0
			3	104	5280	5379	0
			3	107	5730	5849	0
			3	108	5850	5874	2
			3	108	5875	5999	0
			3	109	6000	6149	0
			3	110	6150	6152	2
			3	110	6153	6449	0
			3	111	6450	6532	1
			3	111	6533	6599	0
			3	115	8040	8058	1
			3	115	8059	8631	0
			3	115	8632	8689	1
			3	116	8690	8724	2
			3	116	8725	9039	0
			3	118	9210	9402	0
			3	118	9403	9489	1
			3	118	9490	9542	2
			3	118	9543	9659	0
			3	119	9660	9689	2
			3	119	9690	9769	0
			3	120	9770	9866	1
			3	120	9867	9869	0
			3	122	9920	10301	0
			3	122	10302	10359	1
			3	124	36200	36349	0
			3	128	37750	37784	1
			3	128	37785	38249	0
			3	129	38250	38628	0
			3	129	38629	38649	1
			3	130	38650	39106	0
			3	130	39107	39246	1
			3	130	39247	39649	0
			3	131	39650	39712	1
			3	131	39713	40284	0
			3	131	40285	40424	1
			3	131	40425	40997	0
			3	131	40998	41137	1
			3	131	41138	41589	0
			3	132	41590	41740	0
			3	132	41741	41880	1
			3	132	41881	42452	0
			3	132	42453	42592	1
			3	132	42593	43165	0
			3	132	43166	43305	1
			3	132	43306	43589	0
			3	138	55240	55315	0
			3	138	55316	55455	1
			3	138	55456	56028	0
			3	138	56029	56168	1
			3	138	56169	56739	0
			3	156	66436	66653	0
			3	156	66654	66793	1
			3	156	66794	67335	0
			3	161	68586	68762	0
			3	161	68763	68833	1
			3	161	68834	68902	2
			3	161	68903	68935	0
			4	51	0	0	0
			4	52	0	0	0
			4	53	0	0	1
			4	54	0	0	0
			4	55	0	0	2
			4	56	0	0	1
			5	61	0	0	2
			5	62	0	0	0
			5	71	0	0	2
		>;

		/*
		 * ************************************************************************************************************************
		 *  FD Settings
		 * ************************************************************************************************************************
		 */

		samsung,fd_on_tx_cmds_revA = [
			/* Display PMIC FD On */
			29 00 00 00 00 00 03 F0 5A 5A	/* TEST KEY Enable */
			29 00 00 00 00 00 04 B0 00 0A B5
			29 00 00 00 00 00 03 B5 40 40	/* FD On */
			29 01 00 00 78 00 03 F0 A5 A5	/* TEST KEY Disable */
		];

		samsung,fd_off_tx_cmds_revA = [
			/* Display PMIC FD Off */
			29 00 00 00 00 00 03 F0 5A 5A	/* TEST KEY Enable */
			29 00 00 00 00 00 04 B0 00 0A B5
			29 00 00 00 00 00 03 B5 80 40	/* FD Off */
			29 01 00 00 78 00 03 F0 A5 A5	/* TEST KEY Disable */
		];

		/* *************************************************************
		 *   APLPM
		 * *************************************************************
		 */
		samsung,lpm_on_tx_cmds_revG = [
			29 00 00 00 00 00 03 F0 5A 5A
			29 00 00 00 00 00 03 91 01 01 /* AOD Setting */
			29 00 00 00 00 00 02 53 27
			29 00 00 00 00 00 04 B0 01 88 CB
			29 00 00 00 00 00 08 CB 3C 0D 00 00 00 00 3C /* HFP Setting */
			29 00 00 00 00 00 04 B0 01 C0 CB
			29 00 00 00 00 00 08 CB 38 00 00 00 18 03 38 /* HFP Setting */
			29 00 00 00 00 00 04 B0 00 10 F2
			29 00 00 00 00 00 03 F2 24 A4	/* HFP Setting */
			29 01 00 00 00 00 02 F7 0F 	/* 10ns dealy */
			29 01 00 00 11 00 03 F0 A5 A5 /* wait 16.7ms */
		];

		samsung,lpm_on_tx_cmds_revA = [
			29 00 00 00 00 00 03 F0 5A 5A
			29 00 00 00 00 00 03 91 01 01
			29 01 00 00 00 00 02 53 26	/* 10ns dealy */
			29 00 00 00 00 00 02 F7 0F
			29 01 00 00 11 00 03 F0 A5 A5 /* wait 16.7ms */
		];

		samsung,lpm_off_tx_cmds_revG = [
			29 00 00 00 00 00 03 F0 5A 5A
			29 00 00 00 00 00 04 B0 00 07 B5
			29 00 00 00 00 00 04 B5 00 00 00	/* A SWIRE No Pulse */
			29 00 00 00 00 00 04 B0 01 88 CB
			29 00 00 00 00 00 08 CB 40 0D 00 00 00 00 40 /* HFP Setting*/
			29 00 00 00 00 00 04 B0 01 C0 CB
			29 00 00 00 00 00 08 CB 3D 00 00 00 18 03 3D /* HFP Setting*/
			29 00 00 00 00 00 04 B0 00 10 F2
			29 00 00 00 00 00 03 F2 26 E4 /* HFP Setting*/
			29 00 00 00 00 00 03 91 02 01 /* Normal Setting */
			29 00 00 00 00 00 02 53 20 /* Normal Mode*/
			29 00 00 00 00 00 02 F7 0F
			29 01 00 00 00 00 03 F0 A5 A5 /* wait 33.4ms at lpm code*/
		];

		samsung,lpm_off_tx_cmds_revA = [
			29 00 00 00 00 00 03 F0 5A 5A
			29 00 00 00 00 00 04 B0 00 07 B5
			29 00 00 00 00 00 04 B5 00 00 00	/* A SWIRE No Pulse */
			29 00 00 00 00 00 03 91 02 01
			29 00 00 00 00 00 02 F7 0F
			29 01 00 00 00 00 03 F0 A5 A5
		];

		/* ALPM/HLPM 60/30/10/2nit control */
		samsung,lpm_60nit_tx_cmds_revA = [29 00 00 00 00 00 02 53 24];
		samsung,lpm_30nit_tx_cmds_revA = [29 00 00 00 00 00 02 53 25];
		samsung,lpm_10nit_tx_cmds_revA = [29 00 00 00 00 00 02 53 26];
		samsung,lpm_2nit_tx_cmds_revA = [29 00 00 00 00 00 02 53 27];

		/* HLPM / ALPM brightness Commands: default alpm 2nit */
		samsung,lpm_brightnes_tx_cmds_revA		= [
			29 00 00 00 00 00 03 F0 5A 5A
			29 00 00 00 00 00 02 53 26
			29 00 00 00 00 00 02 F7 0F
			29 01 00 00 00 00 03 F0 A5 A5
		];

		/*
		* ************************************************************************************************************************
		*  DMS (Dynamic Mode Switch)
		* ************************************************************************************************************************
		*/

		qcom,mdss-dsi-display-timings {
			fhd90 {
				qcom,display-topology = <1 0 1>;
				qcom,default-topology-index = <0>;

				qcom,mdss-dsi-panel-width = <1080>;
				qcom,mdss-dsi-panel-height = <2400>;

				qcom,mdss-dsi-h-pulse-width = <84>;
				qcom,mdss-dsi-h-back-porch = <88>;
				qcom,mdss-dsi-h-front-porch = <80>;
				qcom,mdss-dsi-h-sync-skew = <0>;

				qcom,mdss-dsi-v-pulse-width = <2>;
				qcom,mdss-dsi-v-back-porch = <2>;
				qcom,mdss-dsi-v-front-porch = <15>;

				qcom,mdss-dsi-panel-framerate = <90>;
				samsung,mdss-dsi-sot-hs-mode;

				/* transfer time: 48Hz: 20032, 60Hz: 15866, 90HZ: 10311 96Hz: 9616, 120Hz: 7533 */
				qcom,mdss-mdp-transfer-time-us = <9616>;
				qcom,mdss-dsi-panel-clockrate = <1711000000>; /* ((1080 * 2400 * 24 * 96.9869390) / 4 ) ~ 1.9Gbps*/
				qcom,mdss-dsi-panel-phy-timings =[00 36 0F 0E 2D 2A 0F 0F 0D 02 04 00];

				qcom,mdss-dsi-t-clk-pre = <0x2F>;
				qcom,mdss-dsi-t-clk-post = <0x12>;

				qcom,mdss-dsi-on-command = [
					/* Sleep out, wait 30ms(0x1E) */
					05 01 00 00 1E 00 02 11 00

					29 00 00 00 00 00 03 F0 5A 5A
					29 00 00 00 00 00 03 9F A5 A5

					/* Global Para Setting */
					29 00 00 00 00 00 2A F2
						00 05 0E 58 54 00 0C 00
						04 30 B8 30 B8 0C 04 BC
						26 E8 0C 00 04 10 00 10
						26 A8 10 00 10 10 34 10
						00 40 30 C8 00 C8 00 00
						CE
					29 00 00 00 00 00 02 F7 0F

					/* TE Vsync On */
					29 00 00 00 00 00 02 35 00

					/* PAGE Address Setting */
					29 00 00 00 00 00 05 2A 00 00 04 37
					29 00 00 00 00 00 05 2B 00 00 09 5F

					/* Partial update limitation */
					29 00 00 00 00 00 0A C2 1B 41 B0 0E 00 3C 5A 00 00

					/* ERR_FG Setting */
					29 00 00 00 00 00 02 E5 15
					29 00 00 00 00 00 04 ED 44 4C 20

					/* Vsync Setting */

					/* PCD  Setting */
					29 00 00 00 00 00 03 CC 5C 51

					/* Freq setting */
					29 00 00 00 00 00 04 B0 00 27 F2
					29 00 00 00 00 00 02 F2 00

					/* Smooth Dimming 4frame*/
					29 00 00 00 00 00 04 B0 00 92 63
					29 00 00 00 00 00 02 63 04

					/* 90 FPS */
					29 00 00 00 00 00 03 60 08 00

					/* Gamma Update */
					29 00 00 00 00 00 02 F7 0F

					29 00 00 00 00 00 03 9F 5A 5A
					29 01 00 00 5A 00 03 F0 A5 A5 /* wait 90ms */
				];

				qcom,mdss-dsi-off-command = [
					/* DSC PPS cmd unlock & lock LEVEL0 KEY */
					29 00 00 00 00 00 03 9F A5 A5
					05 01 00 00 14 00 02 28 00 /* wait 20ms */
					05 01 00 00 78 00 02 10 00 /* wait 120ms */
					29 01 00 00 00 00 03 9F 5A 5A
				];

				qcom,mdss-dsi-on-command-state = "dsi_hs_mode";
				qcom,mdss-dsi-off-command-state = "dsi_hs_mode";

				//qcom,partial-update-enabled = "single_roi";
				//qcom,panel-roi-alignment=<360 120 360 120 360 120>;
			};

			fhd60 {
				qcom,display-topology = <1 0 1>;
				qcom,default-topology-index = <0>;

				qcom,mdss-dsi-panel-width = <1080>;
				qcom,mdss-dsi-panel-height = <2400>;

				qcom,mdss-dsi-h-pulse-width = <84>;
				qcom,mdss-dsi-h-back-porch = <88>;
				qcom,mdss-dsi-h-front-porch = <80>;
				qcom,mdss-dsi-h-sync-skew = <0>;

				qcom,mdss-dsi-v-pulse-width = <2>;
				qcom,mdss-dsi-v-back-porch = <2>;
				qcom,mdss-dsi-v-front-porch = <16>;

				qcom,mdss-dsi-panel-framerate = <60>;
				samsung,mdss-dsi-sot-hs-mode;

				/* transfer time: 48Hz: 20032, 60Hz: 15866, 90HZ: 10311 96Hz: 9616, 120Hz: 7533 */
				qcom,mdss-mdp-transfer-time-us = <15866>;
				qcom,mdss-dsi-panel-clockrate = <1711000000>; /* ((1080 * 2400 * 24 * 96.9869390) / 4 ) ~ 1.9Gbps*/
				qcom,mdss-dsi-panel-phy-timings =[00 36 0F 0E 2D 2A 0F 0F 0D 02 04 00];

				qcom,mdss-dsi-t-clk-pre = <0x2F>;
				qcom,mdss-dsi-t-clk-post = <0x12>;

				qcom,mdss-dsi-on-command = [
					/* Sleep out, wait 30ms(0x1E) */
					05 01 00 00 1E 00 02 11 00

					29 00 00 00 00 00 03 F0 5A 5A
					29 00 00 00 00 00 03 9F A5 A5

					/* Global Para Setting */
					29 00 00 00 00 00 2A F2
						00 05 0E 58 54 00 0C 00
						04 30 B8 30 B8 0C 04 BC
						26 E8 0C 00 04 10 00 10
						26 A8 10 00 10 10 34 10
						00 40 30 C8 00 C8 00 00
						CE
					29 00 00 00 00 00 02 F7 0F

					/* TE Vsync On */
					29 00 00 00 00 00 02 35 00

					/* PAGE Address Setting */
					29 00 00 00 00 00 05 2A 00 00 04 37
					29 00 00 00 00 00 05 2B 00 00 09 5F

					/* Partial update limitation */
					29 00 00 00 00 00 0A C2 1B 41 B0 0E 00 3C 5A 00 00

					/* FFC Setting */

					/* ERR_FG Setting */
					29 00 00 00 00 00 02 E5 15
					29 00 00 00 00 00 04 ED 44 4C 20

					/* Vsync Setting */

					/* PCD  Setting */
					29 00 00 00 00 00 03 CC 5C 51

					/* Freq setting */
					29 00 00 00 00 00 04 B0 00 27 F2
					29 00 00 00 00 00 02 F2 00

					/* Smooth Dimming 4frame*/
					29 00 00 00 00 00 04 B0 00 92 63
					29 00 00 00 00 00 02 63 04

					/* 60 FPS */
					29 00 00 00 00 00 03 60 00 00

					/* Gamma Update */
					29 00 00 00 00 00 02 F7 0F

					29 00 00 00 00 00 03 9F 5A 5A
					29 01 00 00 5A 00 03 F0 A5 A5 /* wait 90ms */
				];

				qcom,mdss-dsi-off-command = [
					/* DSC PPS cmd unlock & lock LEVEL0 KEY */
					29 00 00 00 00 00 03 9F A5 A5
					05 01 00 00 14 00 02 28 00 /* wait 20ms */
					05 01 00 00 78 00 02 10 00 /* wait 120ms */
					29 01 00 00 00 00 03 9F 5A 5A
				];

				qcom,mdss-dsi-on-command-state = "dsi_hs_mode";
				qcom,mdss-dsi-off-command-state = "dsi_hs_mode";

				//qcom,partial-update-enabled = "single_roi";
				//qcom,panel-roi-alignment=<360 60 360 60 360 60>;
			};
		};
	};
};
